VERSION ""

NS_ :

BS_:

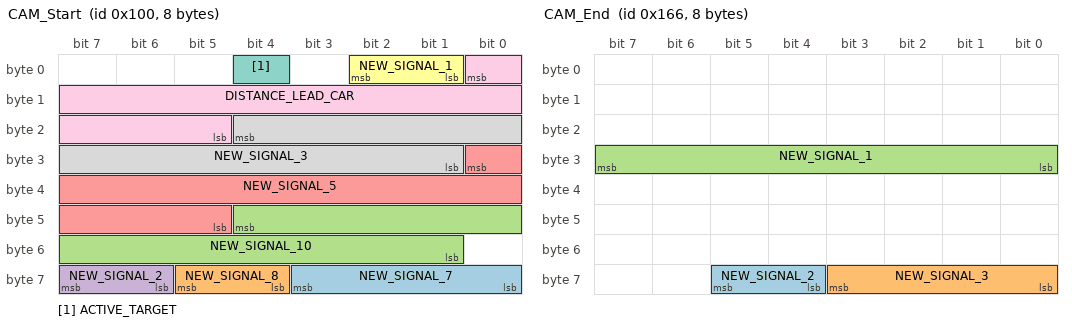
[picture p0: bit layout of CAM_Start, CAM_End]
BO_ 256 CAM_Start: 8 XXX
 SG_ NEW_SIGNAL_7 : 56|4@1+ (1,0) [0|15] "" XXX
 SG_ NEW_SIGNAL_8 : 61|2@0+ (1,0) [0|15] "" XXX
 SG_ NEW_SIGNAL_10 : 44|12@0+ (1,0) [0|15] "" XXX
 SG_ NEW_SIGNAL_2 : 63|2@0+ (1,0) [0|3] "" XXX
 SG_ NEW_SIGNAL_5 : 24|12@0+ (1,0) [0|255] "" XXX
 SG_ NEW_SIGNAL_1 : 2|2@0+ (1,0) [0|1] "" XXX
 SG_ ACTIVE_TARGET : 4|1@0+ (1,0) [0|1] "" XXX
 SG_ NEW_SIGNAL_3 : 20|12@0+ (1,0) [0|7] "" XXX
 SG_ DISTANCE_LEAD_CAR : 0|12@0+ (1,0) [0|255] "" XXX

BO_ 358 CAM_End: 8 XXX
 SG_ NEW_SIGNAL_2 : 61|2@0+ (1,0) [0|3] "" XXX
 SG_ NEW_SIGNAL_3 : 59|4@0+ (1,0) [0|15] "" XXX
 SG_ NEW_SIGNAL_1 : 31|8@0+ (1,0) [0|255] "" XXX

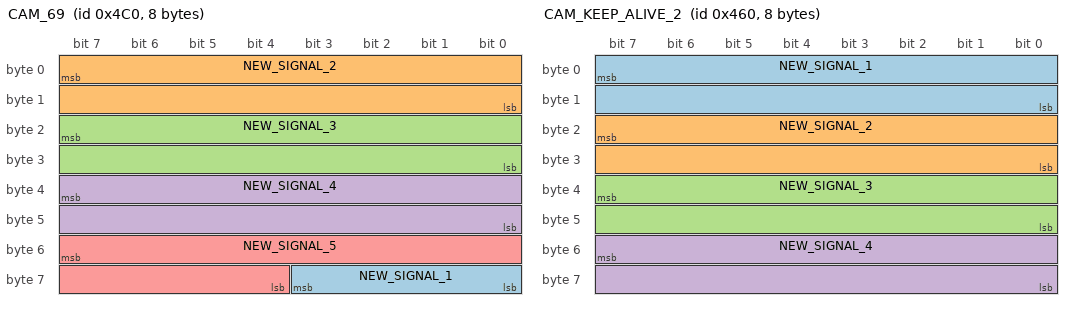
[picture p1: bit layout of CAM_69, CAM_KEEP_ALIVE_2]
BO_ 1216 CAM_69: 8 XXX
 SG_ NEW_SIGNAL_1 : 56|4@1+ (1,0) [0|15] "" XXX
 SG_ NEW_SIGNAL_2 : 7|16@0+ (1,0) [0|65535] "" XXX
 SG_ NEW_SIGNAL_3 : 23|16@0+ (1,0) [0|65535] "" XXX
 SG_ NEW_SIGNAL_4 : 39|16@0+ (1,0) [0|65535] "" XXX
 SG_ NEW_SIGNAL_5 : 55|12@0+ (1,0) [0|7] "" XXX

BO_ 1120 CAM_KEEP_ALIVE_2: 8 XXX
 SG_ NEW_SIGNAL_1 : 7|16@0+ (1,0) [0|65535] "" XXX
 SG_ NEW_SIGNAL_2 : 23|16@0+ (1,0) [0|65535] "" XXX
 SG_ NEW_SIGNAL_3 : 39|16@0+ (1,0) [0|65535] "" XXX
 SG_ NEW_SIGNAL_4 : 55|16@0+ (1,0) [0|65535] "" XXX

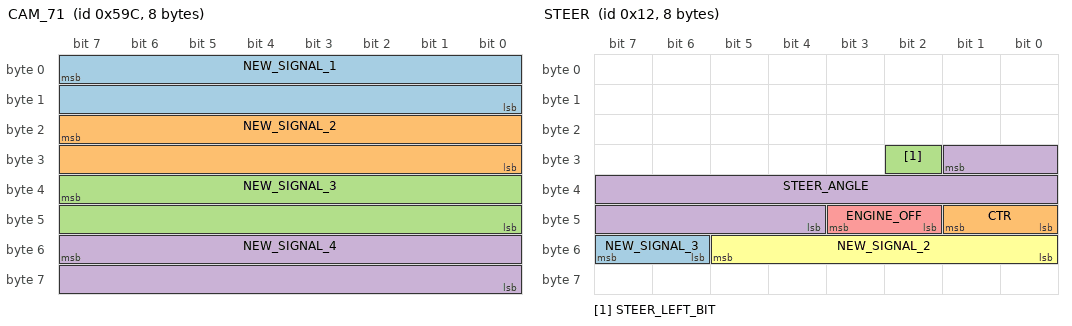
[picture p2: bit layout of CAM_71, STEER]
BO_ 1436 CAM_71: 8 XXX
 SG_ NEW_SIGNAL_1 : 7|16@0+ (1,0) [0|255] "" XXX
 SG_ NEW_SIGNAL_2 : 23|16@0+ (1,0) [0|65535] "" XXX
 SG_ NEW_SIGNAL_3 : 39|16@0+ (1,0) [0|65535] "" XXX
 SG_ NEW_SIGNAL_4 : 55|16@0+ (1,0) [0|65535] "" XXX

BO_ 18 STEER: 8 XXX
 SG_ NEW_SIGNAL_3 : 55|2@0+ (1,0) [0|15] "" XXX
 SG_ CTR : 41|2@0+ (1,0) [0|3] "" XXX
 SG_ STEER_LEFT_BIT : 26|1@0+ (1,0) [0|1] "" XXX
 SG_ STEER_ANGLE : 25|14@0- (1,375) [0|65536] "" XXX
 SG_ ENGINE_OFF : 43|2@0+ (1,0) [0|63] "" XXX
 SG_ NEW_SIGNAL_2 : 53|6@0+ (1,0) [0|15] "" XXX

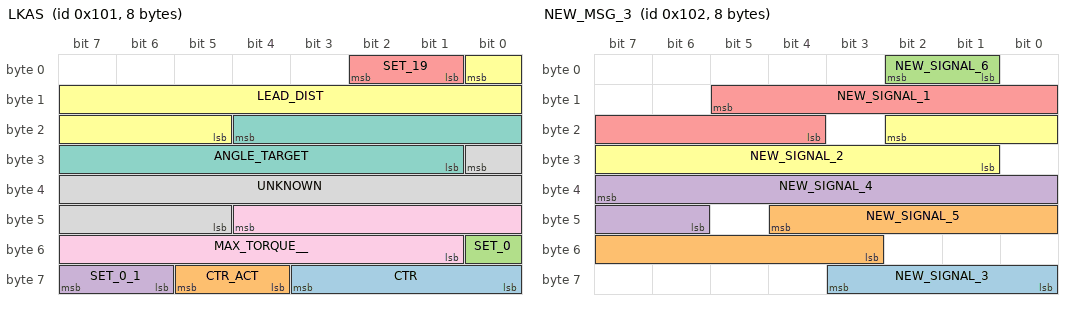
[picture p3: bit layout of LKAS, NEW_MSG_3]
BO_ 257 LKAS: 8 XXX
 SG_ CTR : 59|4@0+ (1,0) [0|255] "" XXX
 SG_ CTR_ACT : 61|2@0+ (1,0) [0|3] "" XXX
 SG_ SET_0 : 48|1@1+ (1,0) [0|3] "" XXX
 SG_ SET_0_1 : 63|2@0+ (1,0) [0|3] "" XXX
 SG_ SET_19 : 2|2@0+ (1,0) [0|255] "" XXX
 SG_ LEAD_DIST : 0|12@0+ (1,0) [0|255] "" XXX
 SG_ ANGLE_TARGET : 20|12@0+ (1,0) [0|4095] "" XXX
 SG_ UNKNOWN : 24|12@0+ (1,0) [0|4095] "" XXX
 SG_ MAX_TORQUE__ : 44|12@0- (1,0) [0|4095] "" XXX

BO_ 258 NEW_MSG_3: 8 XXX
 SG_ NEW_SIGNAL_3 : 59|4@0+ (1,0) [0|255] "" XXX
 SG_ NEW_SIGNAL_5 : 44|10@0- (1,0) [0|1] "" XXX
 SG_ NEW_SIGNAL_6 : 1|2@1+ (1,0) [0|3] "" XXX
 SG_ NEW_SIGNAL_4 : 39|10@0- (1,0) [0|1] "" XXX
 SG_ NEW_SIGNAL_1 : 13|10@0- (1,0) [0|255] "" XXX
 SG_ NEW_SIGNAL_2 : 18|10@0- (1,0) [0|255] "" XXX

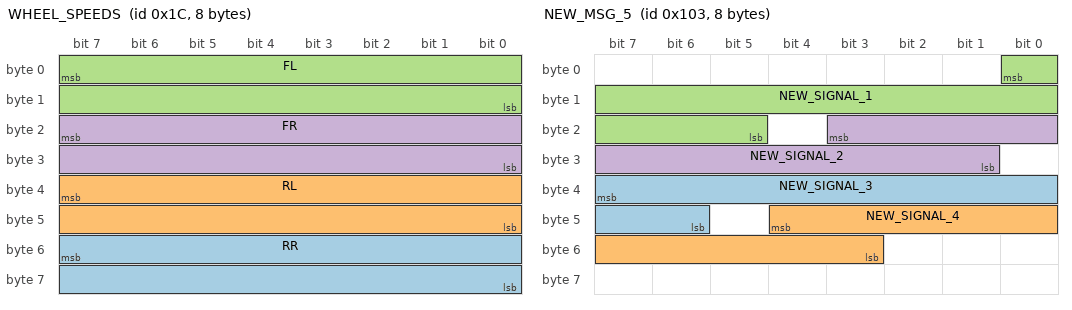
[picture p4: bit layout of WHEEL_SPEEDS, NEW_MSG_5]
BO_ 28 WHEEL_SPEEDS: 8 XXX
 SG_ RR : 55|16@0+ (0.01,-100) [0|65535] "" XXX
 SG_ RL : 39|16@0+ (0.01,-102) [0|65535] "" XXX
 SG_ FL : 7|16@0+ (0.01,-100) [0|65535] "" XXX
 SG_ FR : 23|16@0+ (0.01,-100) [0|65535] "" XXX

BO_ 259 NEW_MSG_5: 8 XXX
 SG_ NEW_SIGNAL_3 : 39|10@0- (1,0) [0|1] "" XXX
 SG_ NEW_SIGNAL_4 : 44|10@0- (1,0) [0|1] "" XXX
 SG_ NEW_SIGNAL_1 : 0|12@0- (1,0) [0|255] "" XXX
 SG_ NEW_SIGNAL_2 : 19|11@0- (1,0) [0|10000000] "" XXX

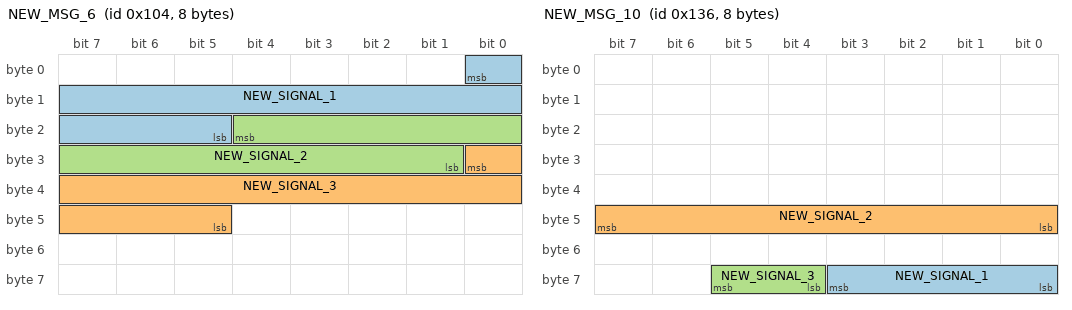
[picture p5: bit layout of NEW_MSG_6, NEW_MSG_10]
BO_ 260 NEW_MSG_6: 8 XXX
 SG_ NEW_SIGNAL_1 : 0|12@0+ (1,0) [0|255] "" XXX
 SG_ NEW_SIGNAL_3 : 24|12@0+ (1,0) [0|1] "" XXX
 SG_ NEW_SIGNAL_2 : 20|12@0- (1,0) [0|1] "" XXX

BO_ 261 NEW_MSG_7: 8 XXX
 SG_ NEW_SIGNAL_1 : 15|8@0+ (1,0) [0|255] "" XXX

BO_ 262 NEW_MSG_8: 8 XXX
 SG_ NEW_SIGNAL_1 : 15|8@0- (1,0) [0|255] "" XXX
 SG_ NEW_SIGNAL_2 : 7|8@0+ (1,0) [0|255] "" XXX

BO_ 263 NEW_MSG_9: 8 XXX
 SG_ NEW_SIGNAL_1 : 15|8@0+ (1,0) [0|255] "" XXX

BO_ 310 NEW_MSG_10: 8 XXX
 SG_ NEW_SIGNAL_1 : 56|4@1+ (1,0) [0|255] "" XXX
 SG_ NEW_SIGNAL_2 : 47|8@0+ (1,0) [0|255] "" XXX
 SG_ NEW_SIGNAL_3 : 61|2@0+ (1,0) [0|3] "" XXX

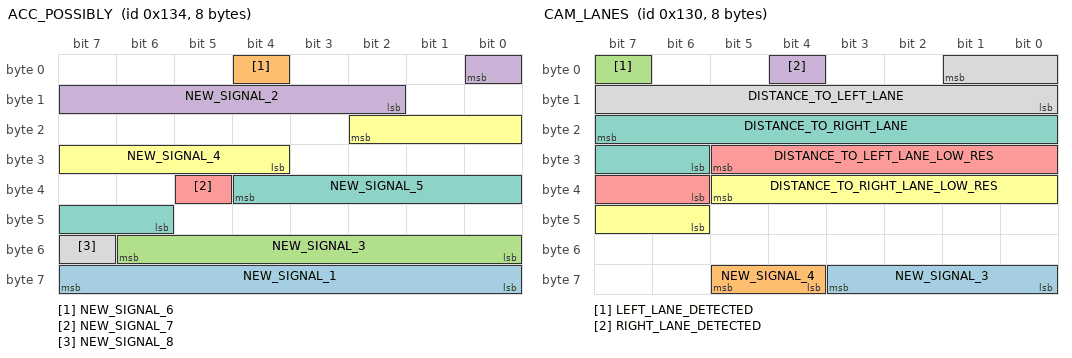
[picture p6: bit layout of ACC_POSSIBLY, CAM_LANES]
BO_ 308 ACC_POSSIBLY: 8 XXX
 SG_ NEW_SIGNAL_1 : 63|8@0+ (1,0) [0|255] "" XXX
 SG_ NEW_SIGNAL_6 : 4|1@0+ (1,0) [0|255] "" XXX
 SG_ NEW_SIGNAL_3 : 54|7@0+ (1,0) [0|15] "" XXX
 SG_ NEW_SIGNAL_2 : 0|7@0+ (1,0) [0|63] "" XXX
 SG_ NEW_SIGNAL_7 : 37|1@0+ (1,0) [0|1] "" XXX
 SG_ NEW_SIGNAL_4 : 18|7@0+ (1,0) [0|15] "" XXX
 SG_ NEW_SIGNAL_5 : 36|7@0+ (1,0) [0|1] "" XXX
 SG_ NEW_SIGNAL_8 : 55|1@0+ (1,0) [0|1] "" XXX

BO_ 304 CAM_LANES: 8 XXX
 SG_ NEW_SIGNAL_3 : 59|4@0+ (1,0) [0|255] "" XXX
 SG_ NEW_SIGNAL_4 : 61|2@0+ (1,0) [0|3] "" XXX
 SG_ LEFT_LANE_DETECTED : 7|1@0+ (1,0) [0|1] "" XXX
 SG_ RIGHT_LANE_DETECTED : 4|1@0+ (1,0) [0|255] "" XXX
 SG_ DISTANCE_TO_LEFT_LANE_LOW_RES : 29|8@0+ (1,0) [0|4095] "" XXX
 SG_ DISTANCE_TO_RIGHT_LANE_LOW_RES : 37|8@0+ (1,0) [0|15] "" XXX
 SG_ DISTANCE_TO_RIGHT_LANE : 23|10@0- (1,0) [0|2047] "" XXX
 SG_ DISTANCE_TO_LEFT_LANE : 1|10@0- (1,0) [0|1] "" XXX

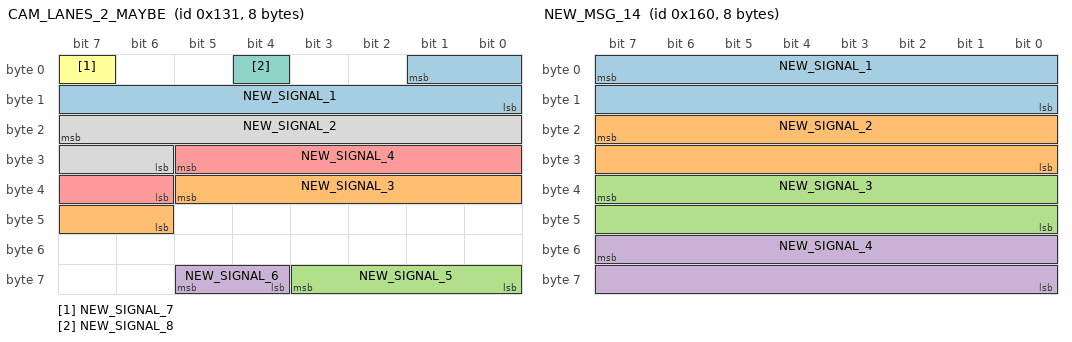
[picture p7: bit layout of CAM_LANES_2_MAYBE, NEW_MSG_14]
BO_ 305 CAM_LANES_2_MAYBE: 8 XXX
 SG_ NEW_SIGNAL_1 : 1|10@0+ (1,0) [0|255] "" XXX
 SG_ NEW_SIGNAL_3 : 37|8@0+ (1,0) [0|15] "" XXX
 SG_ NEW_SIGNAL_5 : 56|4@1+ (1,0) [0|15] "" XXX
 SG_ NEW_SIGNAL_6 : 61|2@0+ (1,0) [0|3] "" XXX
 SG_ NEW_SIGNAL_4 : 29|8@0+ (1,0) [0|1] "" XXX
 SG_ NEW_SIGNAL_7 : 7|1@0+ (1,0) [0|1] "" XXX
 SG_ NEW_SIGNAL_8 : 4|1@0+ (1,0) [0|1] "" XXX
 SG_ NEW_SIGNAL_2 : 23|10@0+ (1,0) [0|4095] "" XXX

BO_ 352 NEW_MSG_14: 8 XXX
 SG_ NEW_SIGNAL_1 : 7|16@0+ (1,0) [0|255] "" XXX
 SG_ NEW_SIGNAL_2 : 23|16@0+ (1,0) [0|65535] "" XXX
 SG_ NEW_SIGNAL_3 : 39|16@0+ (1,0) [0|65535] "" XXX
 SG_ NEW_SIGNAL_4 : 55|16@0+ (1,0) [0|65535] "" XXX

BO_ 355 NEW_MSG_15: 8 XXX
 SG_ NEW_SIGNAL_1 : 7|8@0+ (1,0) [0|127] "" XXX

BO_ 356 NEW_MSG_16: 8 XXX
 SG_ NEW_SIGNAL_1 : 56|4@1+ (1,0) [0|15] "" XXX
 SG_ NEW_SIGNAL_2 : 61|2@0+ (1,0) [0|3] "" XXX

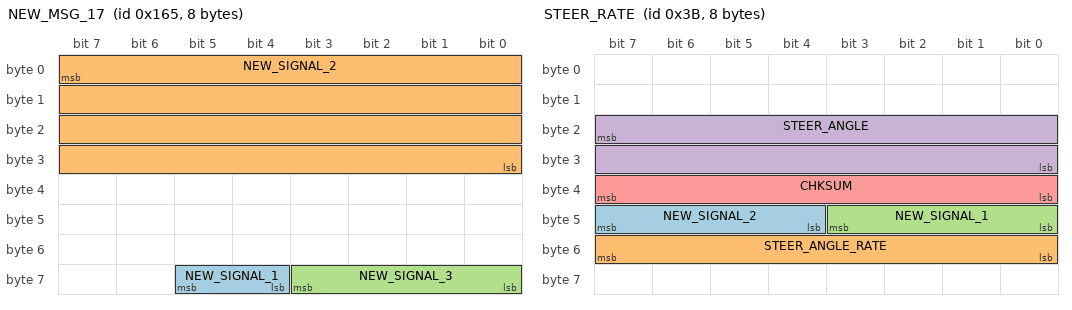
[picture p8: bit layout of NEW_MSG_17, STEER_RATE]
BO_ 357 NEW_MSG_17: 8 XXX
 SG_ NEW_SIGNAL_1 : 61|2@0+ (1,0) [0|3] "" XXX
 SG_ NEW_SIGNAL_2 : 7|32@0+ (1,0) [0|4294967295] "" XXX
 SG_ NEW_SIGNAL_3 : 56|4@1+ (1,0) [0|15] "" XXX

BO_ 59 STEER_RATE: 8 XXX
 SG_ NEW_SIGNAL_2 : 47|4@0+ (1,0) [0|15] "" XXX
 SG_ STEER_ANGLE_RATE : 55|8@0+ (0.05,0) [0|65535] "" XXX
 SG_ NEW_SIGNAL_1 : 43|4@0+ (1,0) [0|15] "" XXX
 SG_ STEER_ANGLE : 23|16@0+ (0.05,-1600) [-500|500] "" XXX
 SG_ CHKSUM : 39|8@0+ (1,0) [0|15] "" XXX

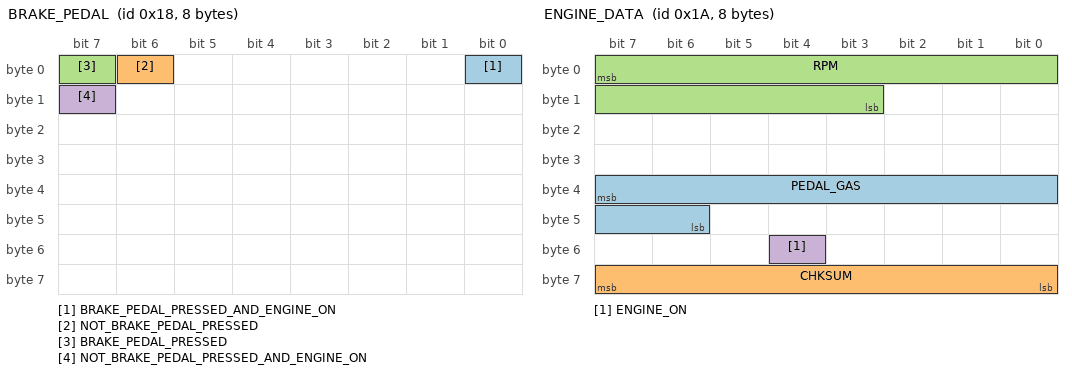
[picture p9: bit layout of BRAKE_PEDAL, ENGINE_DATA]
BO_ 24 BRAKE_PEDAL: 8 XXX
 SG_ BRAKE_PEDAL_PRESSED_AND_ENGINE_ON : 0|1@0+ (1,0) [0|3] "" XXX
 SG_ NOT_BRAKE_PEDAL_PRESSED : 6|1@0+ (1,0) [0|3] "" XXX
 SG_ BRAKE_PEDAL_PRESSED : 7|1@0+ (1,0) [0|65535] "" XXX
 SG_ NOT_BRAKE_PEDAL_PRESSED_AND_ENGINE_ON : 15|1@0+ (1,0) [0|7] "" XXX

BO_ 26 ENGINE_DATA: 8 XXX
 SG_ PEDAL_GAS : 39|10@0+ (1,0) [0|15] "" XXX
 SG_ CHKSUM : 63|8@0- (1,0) [0|15] "" XXX
 SG_ RPM : 7|13@0+ (1,0) [0|15] "" XXX
 SG_ ENGINE_ON : 52|1@0+ (1,0) [0|15] "" XXX

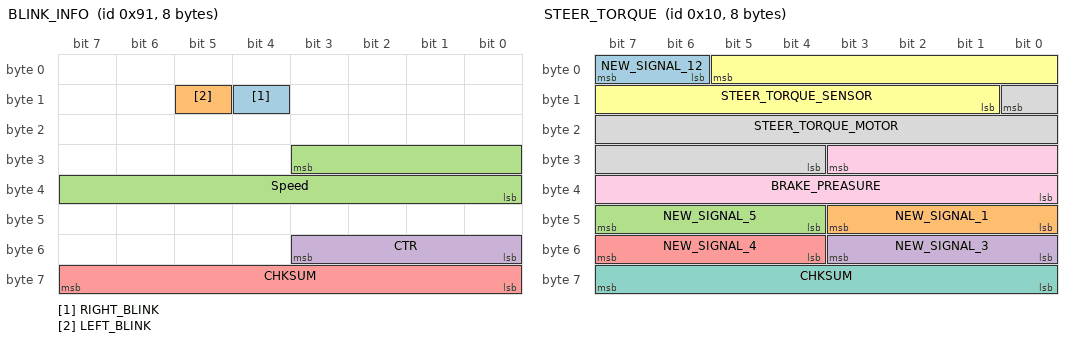
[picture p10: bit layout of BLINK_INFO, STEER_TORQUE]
BO_ 145 BLINK_INFO: 8 XXX
 SG_ RIGHT_BLINK : 12|1@0+ (1,0) [0|3] "" XXX
 SG_ LEFT_BLINK : 13|1@0+ (1,0) [0|3] "" XXX
 SG_ Speed : 27|12@0+ (1,0) [0|255] "" XXX
 SG_ CTR : 51|4@0+ (1,0) [0|15] "" XXX
 SG_ CHKSUM : 63|8@0+ (1,0) [0|15] "" XXX

BO_ 16 STEER_TORQUE: 8 XXX
 SG_ NEW_SIGNAL_12 : 7|2@0+ (1,0) [0|15] "" XXX
 SG_ NEW_SIGNAL_1 : 43|4@0+ (1,0) [0|15] "" XXX
 SG_ NEW_SIGNAL_5 : 47|4@0+ (1,0) [0|15] "" XXX
 SG_ NEW_SIGNAL_3 : 51|4@0+ (1,0) [0|15] "" XXX
 SG_ NEW_SIGNAL_4 : 55|4@0+ (1,0) [0|15] "" XXX
 SG_ STEER_TORQUE_SENSOR : 5|13@0+ (1,-4000) [0|15] "" XXX
 SG_ CHKSUM : 63|8@0- (1,0) [0|15] "" XXX
 SG_ STEER_TORQUE_MOTOR : 8|13@0+ (0.05,-205) [0|15] "" XXX
 SG_ BRAKE_PREASURE : 27|12@0+ (1,0) [0|15] "" XXX

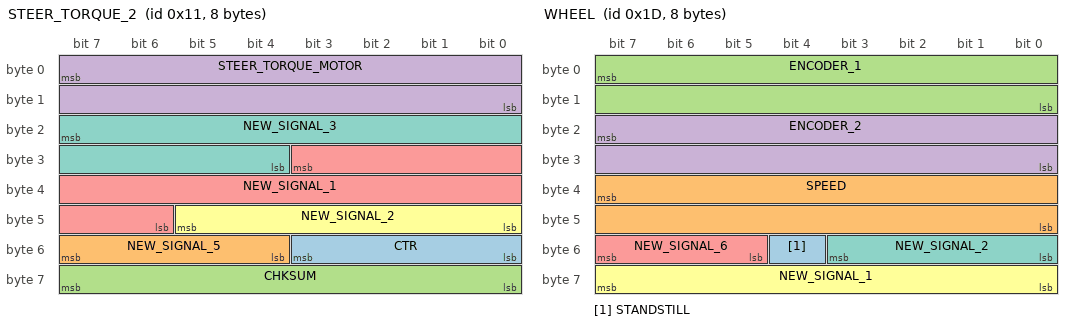
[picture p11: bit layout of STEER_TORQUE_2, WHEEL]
BO_ 17 STEER_TORQUE_2: 8 XXX
 SG_ CTR : 51|4@0+ (1,0) [0|15] "" XXX
 SG_ NEW_SIGNAL_5 : 55|4@0+ (1,0) [0|15] "" XXX
 SG_ CHKSUM : 63|8@0+ (1,0) [0|255] "" XXX
 SG_ STEER_TORQUE_MOTOR : 7|16@0+ (1,0) [0|255] "" XXX
 SG_ NEW_SIGNAL_1 : 27|14@0+ (1,0) [0|255] "" XXX
 SG_ NEW_SIGNAL_2 : 45|6@0+ (1,0) [0|15] "" XXX
 SG_ NEW_SIGNAL_3 : 23|12@0+ (1,0) [0|255] "" XXX

BO_ 29 WHEEL: 8 XXX
 SG_ STANDSTILL : 52|1@0+ (1,0) [0|15] "" XXX
 SG_ SPEED : 39|16@0+ (1,0) [0|127] "" XXX
 SG_ ENCODER_1 : 7|16@0+ (1,0) [0|65535] "" XXX
 SG_ ENCODER_2 : 23|16@0+ (1,0) [0|65535] "" XXX
 SG_ NEW_SIGNAL_6 : 55|3@0+ (1,0) [0|7] "" XXX
 SG_ NEW_SIGNAL_1 : 63|8@0+ (1,0) [0|255] "" XXX
 SG_ NEW_SIGNAL_2 : 51|4@0+ (1,0) [0|15] "" XXX

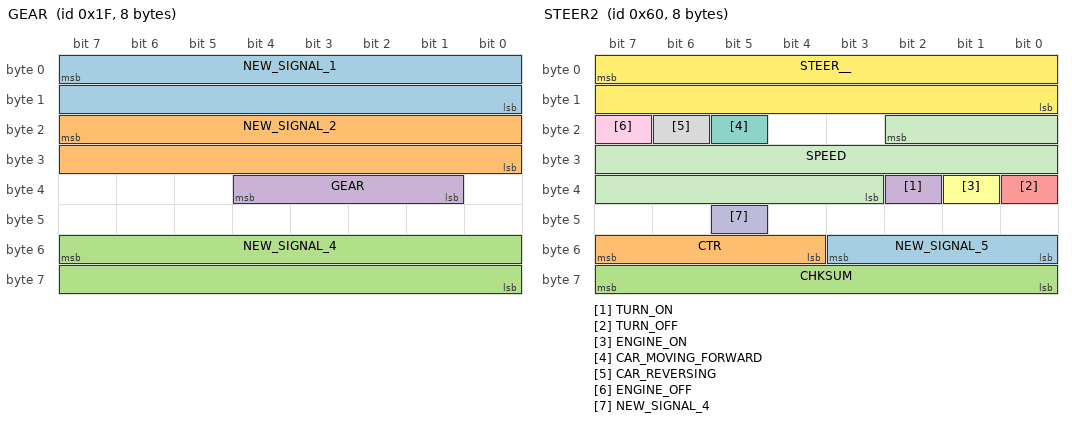
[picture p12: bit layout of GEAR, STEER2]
BO_ 31 GEAR: 8 XXX
 SG_ NEW_SIGNAL_1 : 7|16@0+ (1,0) [0|65535] "" XXX
 SG_ NEW_SIGNAL_2 : 23|16@0+ (1,0) [0|65535] "" XXX
 SG_ NEW_SIGNAL_4 : 55|16@0+ (1,0) [0|65535] "" XXX
 SG_ GEAR : 36|4@0+ (1,0) [0|65535] "" XXX

BO_ 96 STEER2: 8 XXX
 SG_ NEW_SIGNAL_5 : 48|4@1+ (1,0) [0|15] "" XXX
 SG_ CTR : 55|4@0+ (1,0) [0|15] "" XXX
 SG_ CHKSUM : 63|8@0+ (1,0) [0|255] "" XXX
 SG_ TURN_ON : 34|1@0+ (1,0) [0|1] "" XXX
 SG_ TURN_OFF : 32|1@0+ (1,0) [0|1] "" XXX
 SG_ ENGINE_ON : 33|1@0+ (1,0) [0|1] "" XXX
 SG_ CAR_MOVING_FORWARD : 21|1@0+ (1,0) [0|15] "" XXX
 SG_ CAR_REVERSING : 22|1@0+ (1,0) [0|1] "" XXX
 SG_ ENGINE_OFF : 23|1@0+ (1,0) [0|1] "" XXX
 SG_ NEW_SIGNAL_4 : 45|1@0+ (1,0) [0|15] "" XXX
 SG_ SPEED : 18|16@0- (0.00621371,-62.1371) [-65635|65635] "MPH" XXX
 SG_ STEER__ : 7|16@0+ (1,0) [0|65535] "" XXX

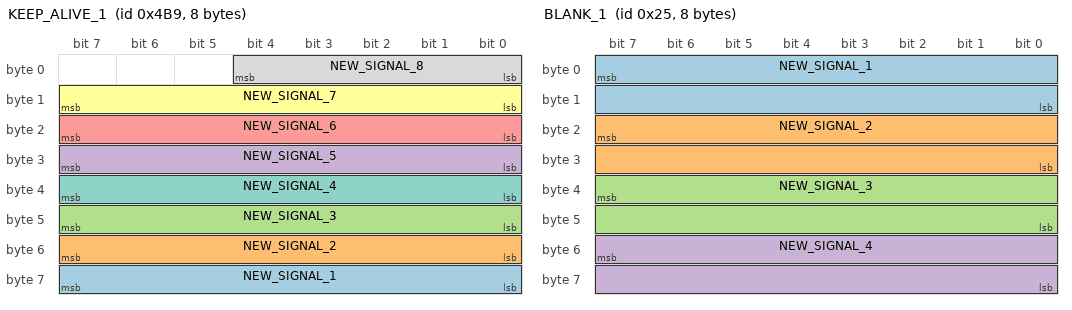
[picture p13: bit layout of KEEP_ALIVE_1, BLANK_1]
BO_ 1209 KEEP_ALIVE_1: 8 XXX
 SG_ NEW_SIGNAL_1 : 63|8@0+ (1,0) [0|255] "" XXX
 SG_ NEW_SIGNAL_2 : 55|8@0+ (1,0) [0|255] "" XXX
 SG_ NEW_SIGNAL_3 : 47|8@0+ (1,0) [0|255] "" XXX
 SG_ NEW_SIGNAL_5 : 31|8@0+ (1,0) [0|255] "" XXX
 SG_ NEW_SIGNAL_6 : 23|8@0+ (1,0) [0|255] "" XXX
 SG_ NEW_SIGNAL_7 : 15|8@0+ (1,0) [0|255] "" XXX
 SG_ NEW_SIGNAL_4 : 39|8@0+ (1,0) [0|255] "" XXX
 SG_ NEW_SIGNAL_8 : 4|5@0+ (1,0) [0|127] "" XXX

BO_ 37 BLANK_1: 8 XXX
 SG_ NEW_SIGNAL_1 : 7|16@0+ (1,0) [0|65535] "" XXX
 SG_ NEW_SIGNAL_2 : 23|16@0+ (1,0) [0|65535] "" XXX
 SG_ NEW_SIGNAL_3 : 39|16@0+ (1,0) [0|65535] "" XXX
 SG_ NEW_SIGNAL_4 : 55|16@0+ (1,0) [0|65535] "" XXX

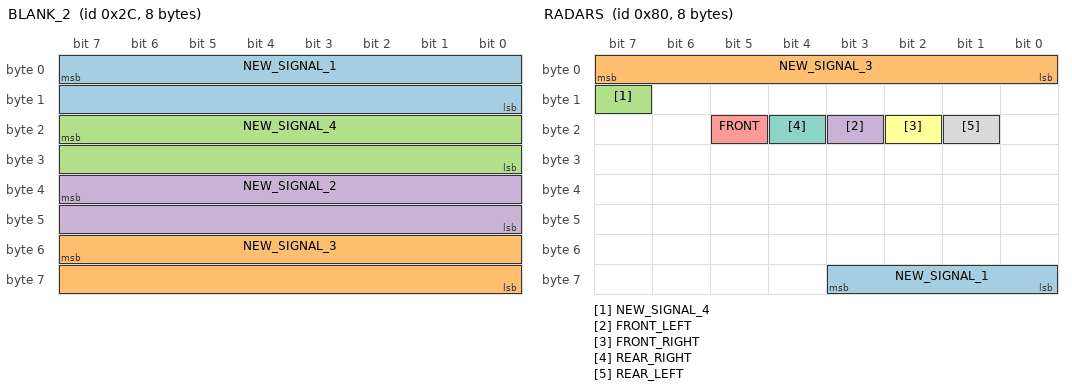
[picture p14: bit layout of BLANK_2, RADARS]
BO_ 44 BLANK_2: 8 XXX
 SG_ NEW_SIGNAL_1 : 7|16@0+ (1,0) [0|16777215] "" XXX
 SG_ NEW_SIGNAL_3 : 55|16@0+ (1,0) [0|65535] "" XXX
 SG_ NEW_SIGNAL_4 : 23|16@0+ (1,0) [0|65535] "" XXX
 SG_ NEW_SIGNAL_2 : 39|16@0+ (1,0) [0|16777215] "" XXX

BO_ 128 RADARS: 8 XXX
 SG_ NEW_SIGNAL_1 : 59|4@0+ (1,0) [0|255] "" XXX
 SG_ NEW_SIGNAL_3 : 7|8@0+ (1,0) [0|255] "" XXX
 SG_ NEW_SIGNAL_4 : 15|1@0+ (1,0) [0|255] "" XXX
 SG_ FRONT_LEFT : 19|1@0+ (1,0) [0|255] "" XXX
 SG_ FRONT : 21|1@0+ (1,0) [0|1] "" XXX
 SG_ FRONT_RIGHT : 18|1@0+ (1,0) [0|1] "" XXX
 SG_ REAR_RIGHT : 20|1@0+ (1,0) [0|15] "" XXX
 SG_ REAR_LEFT : 17|1@0+ (1,0) [0|1] "" XXX

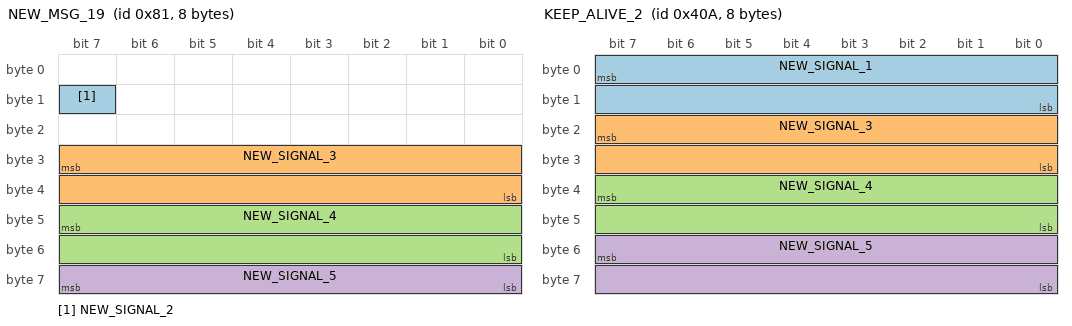
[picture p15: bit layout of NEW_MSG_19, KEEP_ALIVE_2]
BO_ 129 NEW_MSG_19: 8 XXX
 SG_ NEW_SIGNAL_2 : 15|1@0+ (1,0) [0|65535] "" XXX
 SG_ NEW_SIGNAL_3 : 31|16@0+ (1,0) [0|65535] "" XXX
 SG_ NEW_SIGNAL_4 : 47|16@0+ (1,0) [0|65535] "" XXX
 SG_ NEW_SIGNAL_5 : 56|8@1+ (1,0) [0|15] "" XXX

BO_ 1034 KEEP_ALIVE_2: 8 XXX
 SG_ NEW_SIGNAL_1 : 7|16@0+ (1,0) [0|255] "" XXX
 SG_ NEW_SIGNAL_3 : 23|16@0+ (1,0) [0|255] "" XXX
 SG_ NEW_SIGNAL_4 : 39|16@0+ (1,0) [0|255] "" XXX
 SG_ NEW_SIGNAL_5 : 55|16@0+ (1,0) [0|255] "" XXX

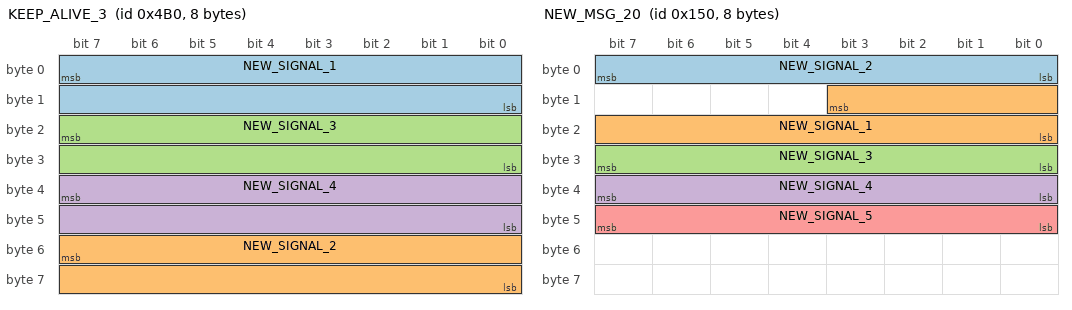
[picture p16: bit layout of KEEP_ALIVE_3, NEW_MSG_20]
BO_ 1200 KEEP_ALIVE_3: 8 XXX
 SG_ NEW_SIGNAL_1 : 7|16@0+ (1,0) [0|255] "" XXX
 SG_ NEW_SIGNAL_2 : 55|16@0+ (1,0) [0|255] "" XXX
 SG_ NEW_SIGNAL_3 : 23|16@0+ (1,0) [0|65535] "" XXX
 SG_ NEW_SIGNAL_4 : 39|16@0+ (1,0) [0|65535] "" XXX

BO_ 354 CAM_KEEP_ALIVE_1: 8 XXX
 SG_ NEW_SIGNAL_1 : 7|16@0+ (1,0) [0|65535] "" XXX
 SG_ NEW_SIGNAL_2 : 23|16@0+ (1,0) [0|65535] "" XXX
 SG_ NEW_SIGNAL_3 : 39|16@0+ (1,0) [0|65535] "" XXX
 SG_ NEW_SIGNAL_4 : 55|30@0+ (1,0) [0|65535] "" XXX

BO_ 336 NEW_MSG_20: 8 XXX
 SG_ NEW_SIGNAL_2 : 7|8@0+ (1,0) [0|4095] "" XXX
 SG_ NEW_SIGNAL_1 : 11|12@0+ (1,0) [0|127] "" XXX
 SG_ NEW_SIGNAL_3 : 31|8@0+ (1,0) [0|255] "" XXX
 SG_ NEW_SIGNAL_4 : 39|8@0+ (1,0) [0|255] "" XXX
 SG_ NEW_SIGNAL_5 : 47|8@0+ (1,0) [0|255] "" XXX

BO_ 342 NEW_MSG_21: 8 XXX
 SG_ NEW_SIGNAL_1 : 56|4@1+ (1,0) [0|15] "" XXX
 SG_ NEW_SIGNAL_2 : 63|4@0+ (1,0) [0|15] "" XXX
 SG_ NEW_SIGNAL_4 : 55|4@0+ (1,0) [0|15] "" XXX
 SG_ NEW_SIGNAL_5 : 39|16@0+ (1,0) [0|15] "" XXX
 SG_ NEW_SIGNAL_3 : 48|4@1+ (1,0) [0|15] "" XXX
 SG_ NEW_SIGNAL_7 : 7|16@0+ (1,0) [0|255] "" XXX
 SG_ NEW_SIGNAL_8 : 23|16@0+ (1,0) [0|65535] "" XXX
 SG_ NEW_SIGNAL_6 : 40|4@1+ (1,0) [0|15] "" XXX

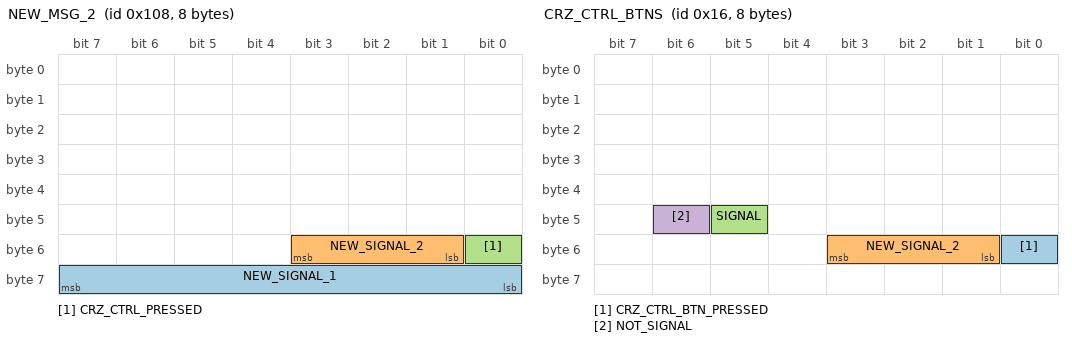
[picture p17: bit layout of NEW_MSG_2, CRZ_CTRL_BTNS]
BO_ 264 NEW_MSG_2: 8 XXX
 SG_ NEW_SIGNAL_1 : 56|8@1+ (1,0) [0|15] "" XXX
 SG_ NEW_SIGNAL_2 : 49|3@1+ (1,0) [0|7] "" XXX
 SG_ CRZ_CTRL_PRESSED : 48|1@0+ (1,0) [0|1] "" XXX

BO_ 22 CRZ_CTRL_BTNS: 8 XXX
 SG_ CRZ_CTRL_BTN_PRESSED : 48|1@0+ (1,0) [0|1] "" XXX
 SG_ NEW_SIGNAL_2 : 51|3@0+ (1,0) [0|7] "" XXX
 SG_ SIGNAL : 45|1@0+ (1,0) [0|15] "" XXX
 SG_ NOT_SIGNAL : 46|1@0+ (1,0) [0|3] "" XXX

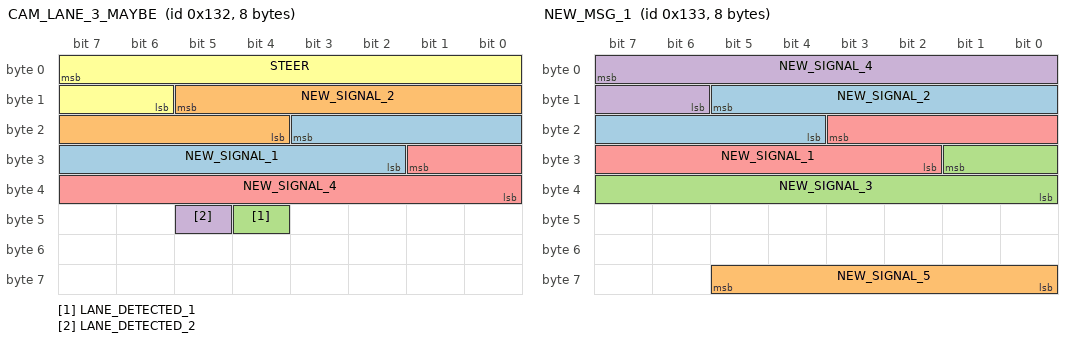
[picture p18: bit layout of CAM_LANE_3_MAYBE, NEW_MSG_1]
BO_ 306 CAM_LANE_3_MAYBE: 8 XXX
 SG_ NEW_SIGNAL_1 : 19|10@0+ (1,0) [0|63] "" XXX
 SG_ NEW_SIGNAL_2 : 13|10@0+ (1,0) [0|255] "" XXX
 SG_ LANE_DETECTED_1 : 44|1@0+ (1,0) [0|1] "" XXX
 SG_ LANE_DETECTED_2 : 45|1@0+ (1,0) [0|1] "" XXX
 SG_ NEW_SIGNAL_4 : 25|10@0+ (1,0) [0|1] "" XXX
 SG_ STEER : 7|10@0+ (1,0) [0|1] "" XXX

BO_ 307 NEW_MSG_1: 8 XXX
 SG_ NEW_SIGNAL_2 : 13|10@0+ (1,0) [0|1] "" XXX
 SG_ NEW_SIGNAL_5 : 61|6@0+ (1,0) [0|1] "" XXX
 SG_ NEW_SIGNAL_3 : 25|10@0+ (1,0) [0|1] "" XXX
 SG_ NEW_SIGNAL_4 : 7|10@0+ (1,0) [0|1] "" XXX
 SG_ NEW_SIGNAL_1 : 19|10@0+ (1,0) [0|1] "" XXX

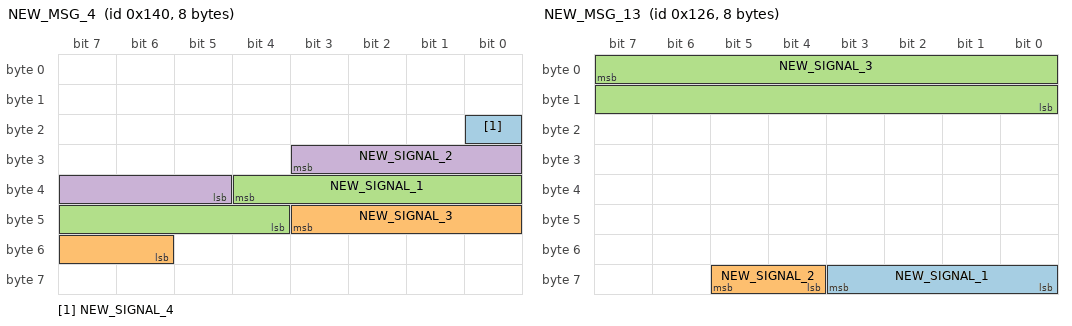
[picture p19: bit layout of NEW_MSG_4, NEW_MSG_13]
BO_ 320 NEW_MSG_4: 8 XXX
 SG_ NEW_SIGNAL_4 : 16|1@0+ (1,0) [0|255] "" XXX
 SG_ NEW_SIGNAL_3 : 43|6@0+ (1,0) [0|1] "" XXX
 SG_ NEW_SIGNAL_1 : 36|9@0+ (1,0) [0|1] "" XXX
 SG_ NEW_SIGNAL_2 : 27|7@0+ (1,0) [0|1] "" XXX

BO_ 321 NEW_MSG_11: 8 XXX
 SG_ NEW_SIGNAL_1 : 5|1@0+ (1,0) [0|1] "" XXX
 SG_ NEW_SIGNAL_2 : 32|1@0+ (1,0) [0|1] "" XXX

BO_ 293 NEW_MSG_12: 8 XXX
 SG_ NEW_SIGNAL_1 : 7|8@0+ (1,0) [0|255] "" XXX
 SG_ NEW_SIGNAL_2 : 39|16@0+ (1,0) [0|255] "" XXX
 SG_ NEW_SIGNAL_3 : 19|4@0+ (1,0) [0|1] "" XXX

BO_ 294 NEW_MSG_13: 8 XXX
 SG_ NEW_SIGNAL_1 : 59|4@0+ (1,0) [0|255] "" XXX
 SG_ NEW_SIGNAL_2 : 61|2@0+ (1,0) [0|1] "" XXX
 SG_ NEW_SIGNAL_3 : 7|16@0+ (1,0) [0|1] "" XXX

BO_ 292 NEW_MSG_18: 8 XXX
 SG_ NEW_SIGNAL_1 : 63|8@0+ (1,0) [0|255] "" XXX

BO_ 291 NEW_MSG_22: 8 XXX
 SG_ NEW_SIGNAL_1 : 39|8@0+ (1,0) [0|255] "" XXX

BO_ 290 NEW_MSG_23: 8 XXX
 SG_ NEW_SIGNAL_1 : 31|5@0+ (1,0) [0|255] "" XXX

BO_ 277 NEW_MSG_24: 8 XXX
 SG_ NEW_SIGNAL_1 : 47|8@0+ (1,0) [0|1] "" XXX

BO_ 278 NEW_MSG_25: 8 XXX

BO_ 273 NEW_MSG_26: 8 XXX
 SG_ NEW_SIGNAL_1 : 23|4@0+ (1,0) [0|3] "" XXX

BO_ 274 NEW_MSG_27: 8 XXX
 SG_ NEW_SIGNAL_1 : 39|8@0+ (1,0) [0|1] "" XXX

BO_ 289 NEW_MSG_28: 8 XXX
 SG_ NEW_SIGNAL_1 : 55|8@0+ (1,0) [0|1] "" XXX

BO_ 20 NEW_MSG_29: 8 XXX
 SG_ RIGHT_BLINK_CLOCK : 23|8@0+ (1,0) [0|1] "" XXX

BO_ 288 NEW_MSG_30: 8 XXX

BU_: PowertrainControlModule InstrumentCluster ElectricPowerSteering AntilockBrakeSystem

CM_ "AUTOGENERATED FILE, DO NOT EDIT";

CM_ "Imported file _subaru_global.dbc starts here";
CM_ SG_ 64 Throttle_Combo "Throttle Cruise + Pedal";
CM_ SG_ 313 Brake_Lights "Driver or Cruise Brake on";
CM_ SG_ 544 Cruise_Brake_Lights "1 = switch on brake lights";
CM_ SG_ 544 Brake_Pressure "Winds down after cruise disabled. Also can be non-zero when likely preparing for AEB";
CM_ SG_ 544 Signal3 "Usually goes to 2 if AEB_Status is 4";
CM_ SG_ 544 AEB_Status "Occasionally is 4 instead of 8 while Brake_Pressure is non-zero, unsure why";
CM_ SG_ 801 PCB_Off "Pre-Collision Braking off";
CM_ SG_ 801 Brake_Lights "Driver or Cruise brake on";
CM_ SG_ 801 Cruise_State "0 = Normal, 1 = Hold+User Brake, 2 = Ready, 3 = Hold";
CM_ SG_ 801 Far_Distance "1=0-5m, 2=5-10m, 3=10-15m, 4=15-20m, 5=20-25m, 6=25-30m, 7=30-35m, 8=35-40m, 9=40-45m, 10=45-50m, 11=50-55m, 12=55-60m, 13=60-65m, 14=65-70m, 15=75m+";
CM_ SG_ 801 LKAS_State_Msg "1 = LKAS_Off_Sharp_Curve, 2 = Keep_Hands_On_Steering_wheel_disabled, 3 = LKAS_Off, 4 = LKAS_Off_Too_Slow, 5 = LKAS_Off_Too_Fast";
CM_ SG_ 801 Cruise_State_Msg "1 = Cruise_Off_Steep_Slope, 2 = Cruise_lvl1_eco, 3 = Cruise_lvl2_comfort, 4 = Cruise_off_empty_reason, 5 = Cruise_off, 6 = Cruise_Unable_to_set, 7 = Cruise_Unable_to_set_brakes_applied, 8 = Eyesight_not_ready, 9 = Cruise_lvl3_standard, 10 = Cruise_lvl4_dynamic, 11 = Cruise_Unable_to_set_steep_slope";
CM_ SG_ 801 Cruise_Soft_Disable "Eyesight soft disable (eg direct sunlight)";
CM_ SG_ 801 Cruise_Status_Msg "1 = Disabled_Bad_Visibility, 2 = Disabled_Check_Manual";
CM_ SG_ 802 LKAS_ACTIVE "Turns on the full LKAS dash display";
CM_ SG_ 802 LKAS_Alert_Msg "1 = Keep_Hands_On_Wheel, 6 = Pre_Collision_Braking, 7 = Keep_Hands_On_Wheel_Off";
CM_ SG_ 802 LKAS_Alert "1 = FCW_Cont_Beep, 2 = FCW_Repeated_Beep, 3 = Throttle_Management_Activated_Warning, 4 = Throttle_Management_Activated_Alert, 5 = Pre_Collision_Activated_Alert, 8 = Traffic_Light_Ahead, 9 = Apply_Brake_to_Hold Position, 11 = LDW_Right, 12 = LDW_Left, 13 = Stay_Alert, 14 = Lead_Vehicle_Start_Alert, 18 = Keep_Hands_On_Steering_Alert, 24 = Audio_Beep, 25 = Audio_Lead_Car_Change, 26 = Audio_ACC_Disengaged, 27 = Audio_LKAS_disabled, 28 = Audio_Ding_Ding, 30 = Audio_Repeated_Beep";
CM_ SG_ 802 LKAS_Left_Line_Visible "0 = Off, 1 = White, 2 = Green, 3 = Orange";
CM_ SG_ 802 LKAS_Dash_State "0 = Off, 1 = Ready, 2 = Active";
CM_ SG_ 802 LKAS_Right_Line_Visible "0 = Off, 1 = White, 2 = Green, 3 = Orange";
CM_ SG_ 912 UNITS "0 = Metric, 1 = Imperial";
CM_ SG_ 912 ICY_ROAD "1 = DASHLIGHT ON, 2 = WARNING, 3 = OFF";
CM_ "subaru_global_2020_hybrid.dbc starts here";

VAL_ 3 StW_Angl 16383 "SNA" ;
VAL_ 3 StW_AnglSens_Id 2 "MUST" 0 "PSBL" 1 "SELF" ;
VAL_ 3 StW_AnglSens_Stat 2 "ERR" 3 "ERR_INI" 1 "INI" 0 "OK" ;
VAL_ 3 StW_AnglSpd 16383 "SNA" ;
VAL_ 14 StW_AnglHP 16383 "SNA" ;
VAL_ 14 StW_AnglHP_Spd 16383 "SNA" ;
VAL_ 14 StW_AnglHP_Sens_Stat 3 "SNA" 2 "ERR" 1 "INI" 0 "OK" ;
VAL_ 14 StW_AnglHP_Sens_Id 3 "SNA" 2 "KOSTAL" 1 "DELPHI" 0 "TEST" ;
VAL_ 69 SpdCtrlLvr_Stat 32 "DN_1ST" 16 "UP_1ST" 8 "DN_2ND" 4 "UP_2ND" 2 "RWD" 1 "FWD" 0 "IDLE" ;
VAL_ 69 DTR_Dist_Rq 255 "SNA" 200 "ACC_DIST_7" 166 "ACC_DIST_6" 133 "ACC_DIST_5" 100 "ACC_DIST_4" 66 "ACC_DIST_3" 33 "ACC_DIST_2" 0 "ACC_DIST_1" ;
VAL_ 69 TurnIndLvr_Stat 3 "SNA" 2 "RIGHT" 1 "LEFT" 0 "IDLE" ;
VAL_ 69 HiBmLvr_Stat 3 "SNA" 2 "HIBM_FLSH_ON_PSD" 1 "HIBM_ON_PSD" 0 "IDLE" ;
VAL_ 69 WprWashSw_Psd 3 "SNA" 2 "WASH" 1 "TIPWIPE" 0 "NPSD" ;
VAL_ 69 WprWash_R_Sw_Posn_V2 3 "SNA" 2 "WASH" 1 "INTERVAL" 0 "OFF" ;
VAL_ 69 StW_Lvr_Stat 4 "STW_BACK" 3 "STW_FWD" 2 "STW_DOWN" 1 "STW_UP" 0 "NPSD" ;
VAL_ 69 StW_Cond_Psd 3 "SNA" 2 "DOWN" 1 "UP" 0 "NPSD" ;
VAL_ 69 HrnSw_Psd 3 "SNA" 2 "NDEF2" 1 "PSD" 0 "NPSD" ;
VAL_ 69 StW_Sw00_Psd 1 "PRESSED" 0 "NOT_PRESSED_SNA" ;
VAL_ 69 StW_Sw01_Psd 1 "PRESSED" 0 "NOT_PRESSED_SNA" ;
VAL_ 69 StW_Sw03_Psd 1 "PRESSED" 0 "NOT_PRESSED_SNA" ;
VAL_ 69 StW_Sw04_Psd 1 "PRESSED" 0 "NOT_PRESSED_SNA" ;
VAL_ 69 WprSw6Posn 7 "SNA" 6 "STAGE2" 5 "STAGE1" 4 "INTERVAL4" 3 "INTERVAL3" 2 "INTERVAL2" 1 "INTERVAL1" 0 "OFF" ;
VAL_ 257 GTW_epasControlType 0 "WITHOUT" 1 "WITH_ANGLE" 3 "WITH_BOTH" 2 "WITH_TORQUE" ;
VAL_ 109 StW_Sw_Stat3 7 "SNA" 6 "NDEF6" 5 "NDEF5" 4 "NDEF4" 3 "PLUS_MINUS" 2 "MINUS" 1 "PLUS" 0 "NPSD" ;
VAL_ 109 MsgTxmtId 3 "NDEF3" 2 "NDEF2" 1 "SCCM" 0 "EWM" ;
VAL_ 109 TSL_RND_Posn_StW 15 "SNA" 8 "D" 6 "INI" 4 "N_DOWN" 2 "N_UP" 1 "R" 0 "IDLE" ;
VAL_ 109 TSL_P_Psd_StW 3 "SNA" 2 "INI" 1 "PSD" 0 "IDLE" ;
VAL_ 257 GTW_epasEmergencyOn 1 "EMERGENCY_POWER" 0 "NONE" ;
VAL_ 257 GTW_epasLDWEnabled 1 "ALLOWED" 0 "INHIBITED" ;
VAL_ 257 GTW_epasPowerMode 0 "DRIVE_OFF" 1 "DRIVE_ON" 3 "LOAD_SHED" 2 "SHUTTING_DOWN" 15 "SNA" ;
VAL_ 257 GTW_epasTuneRequest 1 "DM_COMFORT" 3 "DM_SPORT" 2 "DM_STANDARD" 0 "FAIL_SAFE_DEFAULT" 4 "RWD_COMFORT" 6 "RWD_SPORT" 5 "RWD_STANDARD" 7 "SNA" ;
VAL_ 264 DI_torqueDriver -4096 "SNA" ;
VAL_ 264 DI_torqueMotor -4096 "SNA" ;
VAL_ 264 DI_soptState 7 "SOPT_TEST_SNA" 4 "SOPT_TEST_NOT_RUN" 3 "SOPT_TEST_PASSED" 2 "SOPT_TEST_FAILED" 1 "SOPT_TEST_IN_PROGRESS" 0 "SOPT_PRE_TEST" ;
VAL_ 264 DI_motorRPM -32768 "SNA" ;
VAL_ 264 DI_pedalPos 255 "SNA" ;
VAL_ 280 DI_torqueEstimate -2048 "SNA" ;
VAL_ 280 DI_gear 7 "DI_GEAR_SNA" 4 "DI_GEAR_D" 3 "DI_GEAR_N" 2 "DI_GEAR_R" 1 "DI_GEAR_P" 0 "DI_GEAR_INVALID" ;
VAL_ 280 DI_brakePedal 1 "Applied" 0 "Not_applied" ;
VAL_ 280 DI_vehicleSpeed 4095 "SNA" ;
VAL_ 280 DI_gearRequest 7 "DI_GEAR_SNA" 4 "DI_GEAR_D" 3 "DI_GEAR_N" 2 "DI_GEAR_R" 1 "DI_GEAR_P" 0 "DI_GEAR_INVALID" ;
VAL_ 280 DI_torqueInterfaceFailure 1 "TORQUE_INTERFACE_FAILED" 0 "TORQUE_INTERFACE_NORMAL" ;
VAL_ 280 DI_brakePedalState 3 "SNA" 2 "INVALID" 1 "ON" 0 "OFF" ;
VAL_ 280 DI_epbParkRequest 1 "Park_requested" 0 "No_request" ;
VAL_ 280 DI_epbInterfaceReady 1 "EPB_INTERFACE_READY" 0 "EPB_INTERFACE_NOT_READY" ;
VAL_ 309 ESP_absBrakeEvent 1 "ACTIVE" 0 "NOT_ACTIVE" ;
VAL_ 309 ESP_brakeDiscWipingActive 1 "ACTIVE" 0 "INACTIVE" ;
VAL_ 309 ESP_brakeLamp 0 "OFF" 1 "ON" ;
VAL_ 309 ESP_espFaultLamp 0 "OFF" 1 "ON" ;
VAL_ 309 ESP_espLampFlash 1 "FLASH" 0 "OFF" ;
VAL_ 309 ESP_hillStartAssistActive 1 "ACTIVE" 0 "INACTIVE" 2 "NOT_AVAILABLE" 3 "SNA" ;
VAL_ 309 ESP_absFaultLamp 0 "OFF" 1 "ON" ;
VAL_ 309 ESP_espOffLamp 0 "OFF" 1 "ON" ;
VAL_ 309 ESP_stabilityControlSts 2 "ENGAGED" 3 "FAULTED" 5 "INIT" 4 "NOT_CONFIGURED" 0 "OFF" 1 "ON" ;
VAL_ 309 ESP_tcLampFlash 1 "FLASH" 0 "OFF" ;
VAL_ 568 UI_mapSpeedLimit 31 "SNA" 30 "UNLIMITED" 29 "LESS_OR_EQ_160" 28 "LESS_OR_EQ_150" 27 "LESS_OR_EQ_140" 26 "LESS_OR_EQ_130" 25 "LESS_OR_EQ_120" 24 "LESS_OR_EQ_115" 23 "LESS_OR_EQ_110" 22 "LESS_OR_EQ_105" 21 "LESS_OR_EQ_100" 20 "LESS_OR_EQ_95" 19 "LESS_OR_EQ_90" 18 "LESS_OR_EQ_85" 17 "LESS_OR_EQ_80" 16 "LESS_OR_EQ_75" 15 "LESS_OR_EQ_70" 14 "LESS_OR_EQ_65" 13 "LESS_OR_EQ_60" 12 "LESS_OR_EQ_55" 11 "LESS_OR_EQ_50" 10 "LESS_OR_EQ_45" 9 "LESS_OR_EQ_40" 8 "LESS_OR_EQ_35" 7 "LESS_OR_EQ_30" 6 "LESS_OR_EQ_25" 5 "LESS_OR_EQ_20" 4 "LESS_OR_EQ_15" 3 "LESS_OR_EQ_10" 2 "LESS_OR_EQ_7" 1 "LESS_OR_EQ_5" 0 "UNKNOWN" ;
VAL_ 569 DAS_leftLineUsage 3 "BLACKLISTED" 2 "FUSED" 1 "AVAILABLE" 0 "REJECTED_UNAVAILABLE" ;
VAL_ 569 DAS_rightLineUsage 3 "BLACKLISTED" 2 "FUSED" 1 "AVAILABLE" 0 "REJECTED_UNAVAILABLE" ;
VAL_ 569 DAS_leftFork 3 "LEFT_FORK_UNAVAILABLE" 2 "LEFT_FORK_SELECTED" 1 "LEFT_FORK_AVAILABLE" 0 "LEFT_FORK_NONE" ;
VAL_ 569 DAS_rightFork 3 "RIGHT_FORK_UNAVAILABLE" 2 "RIGHT_FORK_SELECTED" 1 "RIGHT_FORK_AVAILABLE" 0 "RIGHT_FORK_NONE" ;
VAL_ 521 DAS_locMode 3 "DAS_LOC_DRIVERLESS" 2 "DAS_LOC_RESTRICTED" 1 "DAS_LOC_NORMAL" 0 "DAS_LOC_OFF" ;
VAL_ 521 DAS_locState 7 "DAS_LOC_FAULT_SNA" 6 "DAS_LOC_AEB_ACTIVE" 2 "DAS_LOC_CANCEL_SILENT" 1 "DAS_LOC_CANCEL_GENERIC" 0 "DAS_LOC_HEALTHY" ;
VAL_ 521 DAS_locRequest 4 "DAS_RQ_PARK" 3 "DAS_RQ_HOLD" 2 "DAS_RQ_BACKWARD" 1 "DAS_RQ_FORWARD" 0 "DAS_RQ_IDLE" ;
VAL_ 521 DAS_locJerkMin 255 "SNA" ;
VAL_ 521 DAS_locJerkMax 255 "SNA" ;
VAL_ 521 DAS_locSpeed 2047 "SNA" ;
VAL_ 521 DAS_locAccelMin 511 "SNA" ;
VAL_ 521 DAS_locAccelMax 511 "SNA" ;
VAL_ 522 driverBrakeStatus 2 "APPLIED" 1 "NOT_APPLIED" ;
VAL_ 760 UI_mapSpeedLimitUnits 1 "KPH" 0 "MPH" ;
VAL_ 760 UI_userSpeedOffsetUnits 1 "KPH" 0 "MPH" ;
VAL_ 643 AirTemp_Insd 255 "SNA" ;
VAL_ 643 AirTemp_Outsd 254 "INIT" 255 "SNA" ;
VAL_ 643 Bckl_Sw_RL_Stat_SAM_R 2 "FLT" 1 "NOT" 0 "OK" 3 "SNA" ;
VAL_ 643 Bckl_Sw_RM_Stat_SAM_R 2 "FLT" 1 "NOT" 0 "OK" 3 "SNA" ;
VAL_ 643 Bckl_Sw_RR_Stat_SAM_R 2 "FLT" 1 "NOT" 0 "OK" 3 "SNA" ;
VAL_ 643 DL_RLtch_Stat 1 "CLS" 0 "NDEF0" 2 "OPN" 3 "SNA" ;
VAL_ 643 DrRLtch_FL_Stat 1 "CLS" 0 "NDEF0" 2 "OPN" 3 "SNA" ;
VAL_ 643 DrRLtch_FR_Stat 1 "CLS" 0 "NDEF0" 2 "OPN" 3 "SNA" ;
VAL_ 643 DrRLtch_RL_Stat 1 "CLS" 0 "NDEF0" 2 "OPN" 3 "SNA" ;
VAL_ 643 DrRLtch_RR_Stat 1 "CLS" 0 "NDEF0" 2 "OPN" 3 "SNA" ;
VAL_ 643 EngHd_Stat 1 "CLS" 0 "NDEF0" 2 "OPN" 3 "SNA" ;
VAL_ 643 LgtSens_Night 0 "DAY" 1 "NIGHT" ;
VAL_ 643 MPkBrk_Stat 1 "ENGG" 0 "RELS" ;
VAL_ 643 RevGr_Engg 0 "DISENGG" 1 "ENGG" 2 "NDEF2" 3 "SNA" ;
VAL_ 643 StW_Cond_Stat 3 "BLINK" 1 "NDEF1" 0 "OFF" 2 "ON" ;
VAL_ 643 Trlr_Stat 2 "NDEF2" 0 "NONE" 1 "OK" 3 "SNA" ;
VAL_ 697 DAS_setSpeed 4095 "SNA" ;
VAL_ 697 DAS_accState 15 "FAULT_SNA" 13 "ACC_CANCEL_GENERIC_SILENT" 11 "APC_SELFPARK_START" 10 "APC_UNPARK_COMPLETE" 9 "APC_PAUSE" 8 "APC_ABORT" 7 "APC_COMPLETE" 6 "APC_FORWARD" 5 "APC_BACKWARD" 4 "ACC_ON" 3 "ACC_HOLD" 0 "ACC_CANCEL_GENERIC" ;
VAL_ 697 DAS_aebEvent 3 "AEB_SNA" 2 "AEB_FAULT" 1 "AEB_ACTIVE" 0 "AEB_NOT_ACTIVE" ;
VAL_ 697 DAS_jerkMin 511 "SNA" ;
VAL_ 697 DAS_jerkMax 255 "SNA" ;
VAL_ 697 DAS_accelMin 511 "SNA" ;
VAL_ 697 DAS_accelMax 511 "SNA" ;
VAL_ 792 BOOT_STATE 2 "Init" 3 "SNA" 0 "closed" 1 "open" ;
VAL_ 792 CERRD 1 "CAN error detect" 0 "no Can error detected" ;
VAL_ 792 DAY 1 "Init" 0 "SNA" ;
VAL_ 792 DOOR_STATE_FL 2 "Init" 3 "SNA" 0 "closed" 1 "open" ;
VAL_ 792 DOOR_STATE_FR 2 "Init" 3 "SNA" 0 "closed" 1 "open" ;
VAL_ 792 DOOR_STATE_FrontTrunk 2 "Init" 3 "SNA" 0 "closed" 1 "open" ;
VAL_ 792 DOOR_STATE_RL 2 "Init" 3 "SNA" 0 "closed" 1 "open" ;
VAL_ 792 DOOR_STATE_RR 2 "Init" 3 "SNA" 0 "closed" 1 "open" ;
VAL_ 792 GTW_updateInProgress 1 "IN_PROGRESS" 2 "IN_PROGRESS_NOT_USED" 3 "IN_PROGRESS_SNA" 0 "NOT_IN_PROGRESS" ;
VAL_ 792 Hour 30 "Init" 31 "SNA" ;
VAL_ 792 MCU_factoryMode 1 "FACTORY_MODE" 0 "NORMAL_MODE" ;
VAL_ 792 MCU_transportModeOn 0 "NORMAL_MODE" ;
VAL_ 792 MINUTE 62 "Init" 63 "SNA" ;
VAL_ 792 MONTH 1 "Init" 15 "SNA" ;
VAL_ 792 SECOND 62 "Init" 63 "SNA" ;
VAL_ 792 YEAR 126 "Init" 127 "SNA" ;
VAL_ 872 DI_aebState 2 "ENABLED" 4 "FAULT" 7 "SNA" 1 "STANDBY" 3 "STANDSTILL" 0 "UNAVAILABLE" ;
VAL_ 872 DI_analogSpeed 4095 "SNA" ;
VAL_ 872 DI_cruiseState 2 "ENABLED" 5 "FAULT" 0 "OFF" 4 "OVERRIDE" 7 "PRE_CANCEL" 6 "PRE_FAULT" 1 "STANDBY" 3 "STANDSTILL" ;
VAL_ 872 DI_digitalSpeed 255 "SNA" ;
VAL_ 872 DI_immobilizerState 2 "AUTHENTICATING" 3 "DISARMED" 6 "FAULT" 4 "IDLE" 0 "INIT_SNA" 1 "REQUEST" 5 "RESET" ;
VAL_ 872 DI_speedUnits 1 "KPH" 0 "MPH" ;
VAL_ 872 DI_state 3 "ABORT" 4 "ENABLE" 2 "FAULT" 1 "STANDBY" 0 "UNAVAILABLE" ;
VAL_ 872 DI_systemState 3 "ABORT" 4 "ENABLE" 2 "FAULT" 1 "STANDBY" 0 "UNAVAILABLE" ;
VAL_ 872 DI_vehicleHoldState 2 "BLEND_IN" 4 "BLEND_OUT" 6 "FAULT" 7 "INIT" 5 "PARK" 1 "STANDBY" 3 "STANDSTILL" 0 "UNAVAILABLE" ;
VAL_ 880 EPAS_currentTuneMode 1 "DM_COMFORT" 3 "DM_SPORT" 2 "DM_STANDARD" 0 "FAIL_SAFE_DEFAULT" 4 "RWD_COMFORT" 6 "RWD_SPORT" 5 "RWD_STANDARD" 7 "UNAVAILABLE" ;
VAL_ 880 EPAS_eacErrorCode 14 "EAC_ERROR_EPB_INHIBIT" 3 "EAC_ERROR_HANDS_ON" 7 "EAC_ERROR_HIGH_ANGLE_RATE_REQ" 9 "EAC_ERROR_HIGH_ANGLE_RATE_SAFETY" 6 "EAC_ERROR_HIGH_ANGLE_REQ" 8 "EAC_ERROR_HIGH_ANGLE_SAFETY" 10 "EAC_ERROR_HIGH_MMOT_SAFETY" 11 "EAC_ERROR_HIGH_TORSION_SAFETY" 0 "EAC_ERROR_IDLE" 12 "EAC_ERROR_LOW_ASSIST" 2 "EAC_ERROR_MAX_SPEED" 1 "EAC_ERROR_MIN_SPEED" 13 "EAC_ERROR_PINION_VEL_DIFF" 4 "EAC_ERROR_TMP_FAULT" 5 "EAR_ERROR_MAX_STEER_DELTA" 15 "SNA" ;
VAL_ 880 EPAS_eacStatus 2 "EAC_ACTIVE" 1 "EAC_AVAILABLE" 3 "EAC_FAULT" 0 "EAC_INHIBITED" 4 "SNA" ;
VAL_ 880 EPAS_handsOnLevel 0 "0" 1 "1" 2 "2" 3 "3" ;
VAL_ 880 EPAS_steeringFault 1 "FAULT" 0 "NO_FAULT" ;
VAL_ 880 EPAS_steeringRackForce 1022 "NOT_IN_SPEC" 1023 "SNA" ;
VAL_ 880 EPAS_steeringReduced 0 "NORMAL_ASSIST" 1 "REDUCED_ASSIST" ;
VAL_ 880 EPAS_torsionBarTorque 0 "SEE_SPECIFICATION" 4095 "SNA" 4094 "UNDEFINABLE_DATA" ;
VAL_ 904 MCU_clusterReadyForDrive 0 "NO_SNA" 1 "YES" ;
VAL_ 905 DAS_accSpeedLimit 1023 "SNA" 0 "NONE" ;
VAL_ 905 DAS_pmmObstacleSeverity 7 "PMM_SNA" 6 "PMM_ACCEL_LIMIT" 5 "PMM_CRASH_FRONT" 4 "PMM_CRASH_REAR" 3 "PMM_BRAKE_REQUEST" 2 "PMM_IMMINENT_FRONT" 1 "PMM_IMMINENT_REAR" 0 "PMM_NONE" ;
VAL_ 905 DAS_pmmLoggingRequest 1 "TRUE" 0 "FALSE" ;
VAL_ 905 DAS_activationFailureStatus 2 "LC_ACTIVATION_FAILED_2" 1 "LC_ACTIVATION_FAILED_1" 0 "LC_ACTIVATION_IDLE" ;
VAL_ 905 DAS_pmmUltrasonicsFaultReason 4 "PMM_ULTRASONICS_INVALID_MIA" 3 "PMM_ULTRASONICS_BLOCKED_BOTH" 2 "PMM_ULTRASONICS_BLOCKED_REAR" 1 "PMM_ULTRASONICS_BLOCKED_FRONT" 0 "PMM_ULTRASONICS_NO_FAULT" ;
VAL_ 905 DAS_pmmRadarFaultReason 2 "PMM_RADAR_INVALID_MIA" 1 "PMM_RADAR_BLOCKED_FRONT" 0 "PMM_RADAR_NO_FAULT" ;
VAL_ 905 DAS_pmmSysFaultReason 7 "PMM_FAULT_BRAKE_PEDAL_INHIBIT" 6 "PMM_FAULT_ROAD_TYPE" 5 "PMM_FAULT_DISABLED_BY_USER" 4 "PMM_FAULT_STEERING_ANGLE_RATE" 3 "PMM_FAULT_DI_FAULT" 2 "PMM_FAULT_SPEED" 1 "PMM_FAULT_DAS_DISABLED" 0 "PMM_FAULT_NONE" ;
VAL_ 905 DAS_pmmCameraFaultReason 2 "PMM_CAMERA_INVALID_MIA" 1 "PMM_CAMERA_BLOCKED_FRONT" 0 "PMM_CAMERA_NO_FAULT" ;
VAL_ 905 DAS_ACC_report 24 "ACC_REPORT_BEHAVIOR_REPORT" 23 "ACC_REPORT_CAMERA_ONLY" 22 "ACC_REPORT_RADAR_OBJ_FIVE" 21 "ACC_REPORT_CIPV_CUTTING_OUT" 20 "ACC_REPORT_MCVLR_IN_PATH" 19 "ACC_REPORT_MCVLR_DPP" 18 "ACC_REPORT_FLEET_SPEEDS" 17 "ACC_REPORT_TARGET_MCP" 16 "ACC_REPORT_RADAR_OBJ_TWO" 15 "ACC_REPORT_RADAR_OBJ_ONE" 14 "ACC_REPORT_LC_EXTERNAL_STATE_ACTIVE_RESTRICTED" 13 "ACC_REPORT_LC_EXTERNAL_STATE_ABORTED" 12 "ACC_REPORT_LC_EXTERNAL_STATE_ABORTING" 11 "ACC_REPORT_LC_HANDS_ON_REQD_STRUCK_OUT" 10 "ACC_REPORT_CSA" 9 "ACC_REPORT_TARGET_TYPE_FAULT" 8 "ACC_REPORT_TARGET_TYPE_IPSO" 7 "ACC_REPORT_TARGET_TYPE_TRAFFIC_LIGHT" 6 "ACC_REPORT_TARGET_TYPE_STOP_SIGN" 5 "ACC_REPORT_TARGET_CUTIN" 4 "ACC_REPORT_TARGET_MCVR" 3 "ACC_REPORT_TARGET_MCVL" 2 "ACC_REPORT_TARGET_IN_FRONT_OF_CIPV" 1 "ACC_REPORT_TARGET_CIPV" 0 "ACC_REPORT_TARGET_NONE" ;
VAL_ 905 DAS_lssState 7 "LSS_STATE_OFF" 6 "LSS_STATE_ABORT" 5 "LSS_STATE_BLINDSPOT" 4 "LSS_STATE_MONITOR" 3 "LSS_STATE_ELK" 2 "LSS_STATE_LKA" 1 "LSS_STATE_LDW" 0 "LSS_STATE_FAULT" ;
VAL_ 905 DAS_radarTelemetry 2 "RADAR_TELEMETRY_URGENT" 1 "RADAR_TELEMETRY_NORMAL" 0 "RADAR_TELEMETRY_IDLE" ;
VAL_ 905 DAS_robState 3 "ROB_STATE_MAPLESS" 2 "ROB_STATE_ACTIVE" 1 "ROB_STATE_MEASURE" 0 "ROB_STATE_INHIBITED" ;
VAL_ 905 DAS_driverInteractionLevel 2 "CONTINUED_DRIVER_NOT_INTERACTING" 1 "DRIVER_NOT_INTERACTING" 0 "DRIVER_INTERACTING" ;
VAL_ 905 DAS_ppOffsetDesiredRamp 128 "PP_NO_OFFSET" ;
VAL_ 905 DAS_longCollisionWarning 15 "FCM_LONG_COLLISION_WARNING_SNA" 12 "FCM_LONG_COLLISION_WARNING_VEHICLE_CIPV2" 11 "FCM_LONG_COLLISION_WARNING_VEHICLE_MCVR2" 10 "FCM_LONG_COLLISION_WARNING_VEHICLE_MCVR" 9 "FCM_LONG_COLLISION_WARNING_VEHICLE_MCVL2" 8 "FCM_LONG_COLLISION_WARNING_VEHICLE_MCVL" 7 "FCM_LONG_COLLISION_WARNING_VEHICLE_CUTIN" 6 "FCM_LONG_COLLISION_WARNING_VEHICLE_CIPV" 5 "FCM_LONG_COLLISION_WARNING_TFL_STOPLINE" 4 "FCM_LONG_COLLISION_WARNING_STOPSIGN_STOPLINE" 3 "FCM_LONG_COLLISION_WARNING_IPSO" 2 "FCM_LONG_COLLISION_WARNING_PEDESTRIAN" 1 "FCM_LONG_COLLISION_WARNING_VEHICLE_UNKNOWN" 0 "FCM_LONG_COLLISION_WARNING_NONE" ;
VAL_ 921 autopilotStatus 5 "ACTIVE_NAVIGATE_ON_AUTOPILOT" 4 "ACTIVE_2" 3 "ACTIVE_1" 2 "AVAILABLE" 1 "UNAVAILABLE" 0 "DISABLED" ;
VAL_ 921 DAS_blindSpotRearLeft 3 "SNA" 2 "WARNING_LEVEL_2" 1 "WARNING_LEVEL_1" 0 "NO_WARNING" ;
VAL_ 921 DAS_blindSpotRearRight 3 "SNA" 2 "WARNING_LEVEL_2" 1 "WARNING_LEVEL_1" 0 "NO_WARNING" ;
VAL_ 921 DAS_fusedSpeedLimit 31 "NONE" 0 "UNKNOWN_SNA" ;
VAL_ 921 DAS_suppressSpeedWarning 1 "Suppress_Speed_Warning" 0 "Do_Not_Suppress" ;
VAL_ 921 DAS_visionOnlySpeedLimit 31 "NONE" 0 "UNKNOWN_SNA" ;
VAL_ 921 DAS_heaterState 1 "HEATER_ON" 0 "HEATER_OFF_SNA" ;
VAL_ 921 DAS_forwardCollisionWarning 3 "SNA" 1 "FORWARD_COLLISION_WARNING" 0 "NONE" ;
VAL_ 921 DAS_autoparkReady 1 "AUTOPARK_READY" 0 "AUTOPARK_UNAVAILABLE" ;
VAL_ 921 DAS_sideCollisionAvoid 3 "SNA" 2 "AVOID_RIGHT" 1 "AVOID_LEFT" 0 "NONE" ;
VAL_ 921 DAS_sideCollisionWarning 3 "WARN_LEFT_RIGHT" 2 "WARN_RIGHT" 1 "WARN_LEFT" 0 "NONE" ;
VAL_ 921 DAS_sideCollisionInhibit 1 "INHIBIT" 0 "NO_INHIBIT" ;
VAL_ 921 DAS_csaState 3 "CSA_EXTERNAL_STATE_HOLD" 2 "CSA_EXTERNAL_STATE_ENABLE" 1 "CSA_EXTERNAL_STATE_AVAILABLE" 0 "CSA_EXTERNAL_STATE_UNAVAILABLE" ;
VAL_ 921 DAS_laneDepartureWarning 5 "SNA" 4 "RIGHT_WARNING_SEVERE" 3 "LEFT_WARNING_SEVERE" 2 "RIGHT_WARNING" 1 "LEFT_WARNING" 0 "NONE" ;
VAL_ 921 DAS_fleetSpeedState 3 "FLEETSPEED_HOLD" 2 "FLEETSPEED_ACTIVE" 1 "FLEETSPEED_AVAILABLE" 0 "FLEETSPEED_UNAVAILABLE" ;
VAL_ 921 DAS_autopilotHandsOnState 15 "LC_HANDS_ON_SNA" 8 "LC_HANDS_ON_SUSPENDED" 7 "LC_HANDS_ON_REQD_STRUCK_OUT" 5 "LC_HANDS_ON_REQD_CHIME_2" 4 "LC_HANDS_ON_REQD_CHIME_1" 3 "LC_HANDS_ON_REQD_VISUAL" 2 "LC_HANDS_ON_REQD_NOT_DETECTED" 1 "LC_HANDS_ON_REQD_DETECTED" 0 "LC_HANDS_ON_NOT_REQD" ;
VAL_ 921 DAS_autoLaneChangeState 31 "ALC_SNA" 30 "ALC_ABORT_MISSION_PLAN_INVALID" 29 "ALC_ABORT_TIMEOUT" 28 "ALC_WAITING_HANDS_ON" 27 "ALC_BLOCKED_LANE_TYPE_R" 26 "ALC_BLOCKED_LANE_TYPE_L" 25 "ALC_BLOCKED_VEH_TTC_AND_USS_R" 24 "ALC_BLOCKED_VEH_TTC_R" 23 "ALC_BLOCKED_VEH_TTC_AND_USS_L" 22 "ALC_BLOCKED_VEH_TTC_L" 21 "ALC_UNAVAILABLE_SOLID_LANE_LINE" 20 "ALC_ABORT_OTHER_REASON" 19 "ALC_ABORT_BLINKER_TURNED_OFF" 18 "ALC_ABORT_LC_HEALTH_BAD" 17 "ALC_ABORT_POOR_VIEW_RANGE" 16 "ALC_ABORT_SIDE_OBSTACLE_PRESENT_R" 15 "ALC_ABORT_SIDE_OBSTACLE_PRESENT_L" 14 "ALC_WAITING_FOR_FWD_OBST_TO_PASS_R" 13 "ALC_WAITING_FOR_FWD_OBST_TO_PASS_L" 12 "ALC_WAITING_FOR_SIDE_OBST_TO_PASS_R" 11 "ALC_WAITING_FOR_SIDE_OBST_TO_PASS_L" 10 "ALC_IN_PROGRESS_R" 9 "ALC_IN_PROGRESS_L" 8 "ALC_AVAILABLE_BOTH" 7 "ALC_AVAILABLE_ONLY_R" 6 "ALC_AVAILABLE_ONLY_L" 5 "ALC_UNAVAILABLE_VEHICLE_SPEED" 4 "ALC_UNAVAILABLE_EXITING_HIGHWAY" 3 "ALC_UNAVAILABLE_TP_FOLLOW" 2 "ALC_UNAVAILABLE_SONICS_INVALID" 1 "ALC_UNAVAILABLE_NO_LANES" 0 "ALC_UNAVAILABLE_DISABLED" ;
VAL_ 1001 DAS_headlightRequest 3 "DAS_HEADLIGHT_REQUEST_INVALID" 1 "DAS_HEADLIGHT_REQUEST_ON" 0 "DAS_HEADLIGHT_REQUEST_OFF" ;
VAL_ 1001 DAS_hazardLightRequest 3 "DAS_REQUEST_HAZARDS_SNA" 2 "DAS_REQUEST_HAZARDS_UNUSED" 1 "DAS_REQUEST_HAZARDS_ON" 0 "DAS_REQUEST_HAZARDS_OFF" ;
VAL_ 1001 DAS_wiperSpeed 15 "DAS_WIPER_SPEED_INVALID" 14 "DAS_WIPER_SPEED_14" 13 "DAS_WIPER_SPEED_13" 12 "DAS_WIPER_SPEED_12" 11 "DAS_WIPER_SPEED_11" 10 "DAS_WIPER_SPEED_10" 9 "DAS_WIPER_SPEED_9" 8 "DAS_WIPER_SPEED_8" 7 "DAS_WIPER_SPEED_7" 6 "DAS_WIPER_SPEED_6" 5 "DAS_WIPER_SPEED_5" 4 "DAS_WIPER_SPEED_4" 3 "DAS_WIPER_SPEED_3" 2 "DAS_WIPER_SPEED_2" 1 "DAS_WIPER_SPEED_1" 0 "DAS_WIPER_SPEED_OFF" ;
VAL_ 1001 DAS_turnIndicatorRequest 3 "DAS_TURN_INDICATOR_CANCEL" 2 "DAS_TURN_INDICATOR_RIGHT" 1 "DAS_TURN_INDICATOR_LEFT" 0 "DAS_TURN_INDICATOR_NONE" ;
VAL_ 1001 DAS_highLowBeamDecision 3 "DAS_HIGH_BEAM_SNA" 2 "DAS_HIGH_BEAM_ON" 1 "DAS_HIGH_BEAM_OFF" 0 "DAS_HIGH_BEAM_UNDECIDED" ;
VAL_ 1001 DAS_highLowBeamOffReason 5 "HIGH_BEAM_OFF_REASON_SNA" 4 "HIGH_BEAM_OFF_REASON_HEAD_LIGHT" 3 "HIGH_BEAM_OFF_REASON_AMBIENT_LIGHT" 2 "HIGH_BEAM_OFF_REASON_MOVING_RADAR_TARGET" 1 "HIGH_BEAM_OFF_REASON_MOVING_VISION_TARGET" 0 "HIGH_BEAM_ON" ;
VAL_ 1001 DAS_turnIndicatorRequestReason 6 "DAS_ACTIVE_COMMANDED_LANE_CHANGE" 5 "DAS_CANCEL_FORK" 4 "DAS_CANCEL_LANE_CHANGE" 3 "DAS_ACTIVE_FORK" 2 "DAS_ACTIVE_SPEED_LANE_CHANGE" 1 "DAS_ACTIVE_NAV_LANE_CHANGE" 0 "DAS_NONE" ;
VAL_ 1160 DAS_steeringAngleRequest 16384 "ZERO_ANGLE" ;
VAL_ 1160 DAS_steeringControlType 1 "ANGLE_CONTROL" 3 "DISABLED" 0 "NONE" 2 "RESERVED" ;
